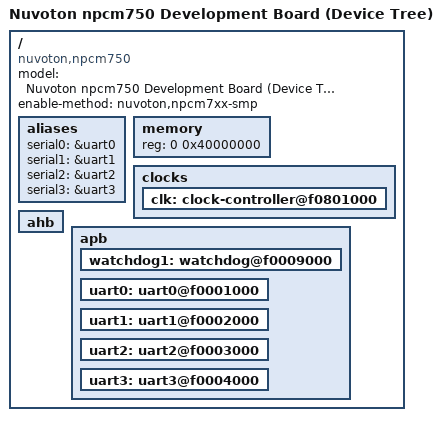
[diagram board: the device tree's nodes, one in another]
/*
 * DTS file for all NPCM750 SoCs
 *
 * Copyright 2012 Tomer Maimon <tomer.maimon@nuvoton.com>
 *
 * The code contained herein is licensed under the GNU General Public
 * License. You may obtain a copy of the GNU General Public License
 * Version 2 or later at the following locations:
 *
 * http://www.opensource.org/licenses/gpl-license.html
 * http://www.gnu.org/copyleft/gpl.html
 */

/dts-v1/;
#include "nuvoton-npcm750.dtsi"

/ {
	model = "Nuvoton npcm750 Development Board (Device Tree)";
	compatible = "nuvoton,npcm750";
	enable-method = "nuvoton,npcm7xx-smp";

	aliases {
		serial0 = &uart0;
		serial1 = &uart1;
		serial2 = &uart2;
		serial3 = &uart3;
	};

	memory {
		reg = <0 0x40000000>;
	};

	clocks {
		clk: clock-controller@f0801000 {
			status = "okay";
		};
	};

	ahb {
	};

	apb {
		watchdog1: watchdog@f0009000 {
			status = "okay";
		};

		uart0: uart0@f0001000 {
			status = "okay";
		};

		uart1: uart1@f0002000 {
			status = "okay";
		};

		uart2: uart2@f0003000 {
			status = "okay";
		};

		uart3: uart3@f0004000 {
			status = "okay";
		};
	};
};
